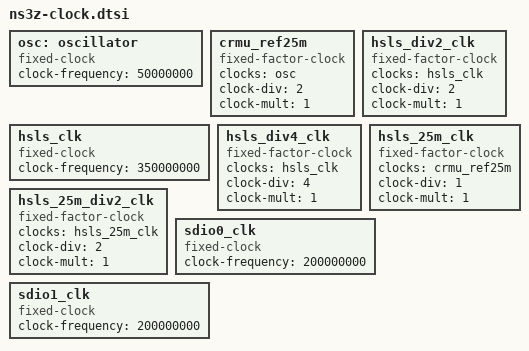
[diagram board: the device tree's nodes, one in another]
// SPDX-License-Identifier: (GPL-2.0 or BSD-3-Clause)
/*
 *  Copyright(c) 2019 Broadcom
 */

#include <dt-bindings/clock/bcm-sr.h>

osc: oscillator {
	#clock-cells = <0>;
	compatible = "fixed-clock";
	clock-frequency = <50000000>;
};

crmu_ref25m: crmu_ref25m {
	#clock-cells = <0>;
	compatible = "fixed-factor-clock";
	clocks = <&osc>;
	clock-div = <2>;
	clock-mult = <1>;
};

hsls_clk: hsls_clk {
	#clock-cells = <0>;
	compatible = "fixed-clock";
	clock-frequency = <350000000>;
};

hsls_div2_clk: hsls_div2_clk {
	#clock-cells = <0>;
	compatible = "fixed-factor-clock";
	clocks = <&hsls_clk>;
	clock-div = <2>;
	clock-mult = <1>;

};

hsls_div4_clk: hsls_div4_clk {
	#clock-cells = <0>;
	compatible = "fixed-factor-clock";
	clocks = <&hsls_clk>;
	clock-div = <4>;
	clock-mult = <1>;
};

hsls_25m_clk: hsls_25m_clk {
	#clock-cells = <0>;
	compatible = "fixed-factor-clock";
	clocks = <&crmu_ref25m>;
	clock-div = <1>;
	clock-mult = <1>;
};

hsls_25m_div2_clk: hsls_25m_div2_clk {
	#clock-cells = <0>;
	compatible = "fixed-factor-clock";
	clocks = <&hsls_25m_clk>;
	clock-div = <2>;
	clock-mult = <1>;
};

sdio0_clk: sdio0_clk {
	#clock-cells = <0>;
	compatible = "fixed-clock";
	clock-frequency = <200000000>;
};

sdio1_clk: sdio1_clk {
	#clock-cells = <0>;
	compatible = "fixed-clock";
	clock-frequency = <200000000>;
};
